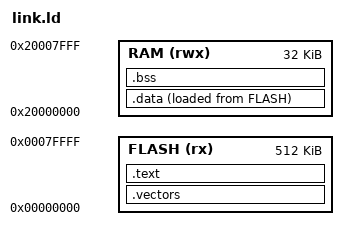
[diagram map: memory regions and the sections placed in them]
ENTRY(Reset_Handler)
MEMORY { FLASH (rx) : ORIGIN = 0x00000000, LENGTH = 512K
         RAM (rwx) : ORIGIN = 0x20000000, LENGTH = 32K }
_stack_top = ORIGIN(RAM) + LENGTH(RAM);
SECTIONS {
 .vectors : { KEEP(*(.vectors)) } > FLASH
 .text : { *(.text*) *(.rodata*) } > FLASH
 .data : { _data_start = .; *(.data*) _data_end = .; } > RAM AT>FLASH
 _data_load = LOADADDR(.data);
 .bss (NOLOAD) : { . = ALIGN(4); _bss_start = .; *(.bss*) *(COMMON) . = ALIGN(4); _bss_end = .; } > RAM
 /DISCARD/ : { *(.ARM.exidx*) *(.ARM.extab*) *(.comment*) }
}
